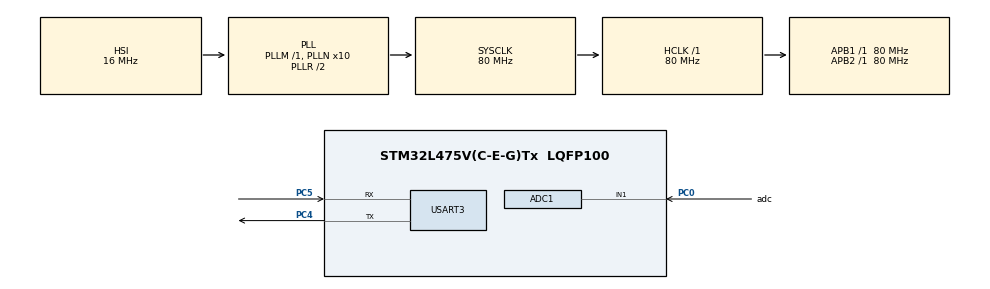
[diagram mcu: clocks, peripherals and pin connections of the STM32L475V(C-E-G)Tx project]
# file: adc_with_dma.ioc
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ADC1.Channel-0\#ChannelRegularConversion=ADC_CHANNEL_1
ADC1.ClockPrescaler=ADC_CLOCK_ASYNC_DIV256
ADC1.ContinuousConvMode=ENABLE
ADC1.DMAContinuousRequests=ENABLE
ADC1.NbrOfConversionFlag=1
ADC1.OffsetNumber-0\#ChannelRegularConversion=ADC_OFFSET_NONE
ADC1.Rank-0\#ChannelRegularConversion=1
ADC1.SamplingTime-0\#ChannelRegularConversion=ADC_SAMPLETIME_92CYCLES_5
ADC1.master=1
Dma.ADC1.0.Direction=DMA_PERIPH_TO_MEMORY
Dma.ADC1.0.Instance=DMA1_Channel1
Dma.ADC1.0.MemDataAlignment=DMA_MDATAALIGN_WORD
Dma.ADC1.0.MemInc=DMA_MINC_ENABLE
Dma.ADC1.0.Mode=DMA_CIRCULAR
Dma.ADC1.0.PeriphDataAlignment=DMA_PDATAALIGN_WORD
Dma.ADC1.0.PeriphInc=DMA_PINC_DISABLE
Dma.ADC1.0.Priority=DMA_PRIORITY_LOW
Dma.Request0=ADC1
Mcu.Family=STM32L4
Mcu.Name=STM32L475V(C-E-G)Tx
Mcu.Package=LQFP100
NVIC.DMA1_Channel1_IRQn=true\:0\:0\:false\:false\:true\:false\:true\:true
NVIC.PriorityGroup=NVIC_PRIORITYGROUP_4
PA13\ (JTMS-SWDIO).Mode=Serial_Wire
PA13\ (JTMS-SWDIO).Signal=SYS_JTMS-SWDIO
PA14\ (JTCK-SWCLK).Mode=Serial_Wire
PA14\ (JTCK-SWCLK).Signal=SYS_JTCK-SWCLK
PC0.GPIO_Label=adc
PC0.Signal=ADCx_IN1
PC4.Mode=Asynchronous
PC4.Signal=USART3_TX
PC5.Mode=Asynchronous
PC5.Signal=USART3_RX
ProjectManager.HeapSize=0x200
ProjectManager.StackSize=0x400
ProjectManager.TargetToolchain=STM32CubeIDE
RCC.ADCFreq_Value=64000000
RCC.AHBFreq_Value=80000000
RCC.APB1Freq_Value=80000000
RCC.APB1TimFreq_Value=80000000
RCC.APB2Freq_Value=80000000
RCC.APB2TimFreq_Value=80000000
RCC.CortexFreq_Value=80000000
RCC.HCLKFreq_Value=80000000
RCC.HSE_VALUE=8000000
RCC.HSI_VALUE=16000000
RCC.LSE_VALUE=32768
RCC.MSI_VALUE=4000000
RCC.PLLN=10
RCC.PLLSourceVirtual=RCC_PLLSOURCE_HSI
RCC.SYSCLKFreq_VALUE=80000000
RCC.SYSCLKSource=RCC_SYSCLKSOURCE_PLLCLK
RCC.USBFreq_Value=64000000
RCC.VCOOutputFreq_Value=160000000
SH.ADCx_IN1.0=ADC1_IN1,IN1-Single-Ended
USART3.VirtualMode-Asynchronous=VM_ASYNC
board=B-L475E-IOT01A2

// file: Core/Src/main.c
/* USER CODE BEGIN Header */
/**
  ******************************************************************************
  * @file           : main.c
  * @brief          : Main program body
  ******************************************************************************
  * @attention
  *
  * Copyright (c) 2024 STMicroelectronics.
  * All rights reserved.
  *
  * This software is licensed under terms that can be found in the LICENSE file
  * in the root directory of this software component.
  * If no LICENSE file comes with this software, it is provided AS-IS.
  *
  ******************************************************************************
  */
/* USER CODE END Header */
#include "main.h"
#include <stdlib.h>

ADC_HandleTypeDef hadc1;
DMA_HandleTypeDef hdma_adc1;

UART_HandleTypeDef huart3;

/* USER CODE BEGIN PV */
uint32_t adc_val;
uint32_t dma_buffer;
uint32_t time;
/* USER CODE END PV */

void SystemClock_Config(void);
static void MX_GPIO_Init(void);
static void MX_DMA_Init(void);
static void MX_ADC1_Init(void);
static void MX_USART3_UART_Init(void);

int main(void)
{

  /* MCU Configuration--------------------------------------------------------*/

  /* Reset of all peripherals, Initializes the Flash interface and the Systick. */
  HAL_Init();

  /* Configure the system clock */
  SystemClock_Config();

  /* Initialize all configured peripherals */
  MX_GPIO_Init();
  MX_DMA_Init();
  MX_ADC1_Init();
  MX_USART3_UART_Init();
  /* USER CODE BEGIN 2 */
  // Attaching the ADC1 to DMA.
  HAL_ADC_Start_DMA(&hadc1, &dma_buffer,1);
  /* USER CODE END 2 */

  /* Infinite loop */
  while (1)
  {
	  time = HAL_GetTick();
	  for(int i = 0; i < 1000000; i++)
	  {
		  // CPU load using a for loop.
	  }
	  time = HAL_GetTick() - time;

	  //Elapsed time calculation, CPU didn't get any interrupt for ADC.
	  // Send elapsed time to terminal using USART3
	  uint8_t time_str[] = "With DMA time: ";
	  HAL_UART_Transmit(&huart3, time_str, sizeof(time_str),10);
	  //Integer to char conversion
	  char time_buf[sizeof(uint32_t)*8+1];
	  utoa(time, time_buf, 10);
	  HAL_UART_Transmit(&huart3, (uint8_t*)time_buf,3,10);

	  // Send ADC value to terminal using USART3
	  uint8_t adc_str[] = " adc val: ";
	  HAL_UART_Transmit(&huart3, adc_str, sizeof(adc_str),10);

	  // Integer to char conversion.
	  char adc_buf[sizeof(uint32_t)*8+2+1];// size of uint32_t = 4bytes = 32 bits + 1 NULL char + \r \n
	  utoa(adc_val, adc_buf, 10);
	  adc_buf[5] = '\n';
	  adc_buf[4] = '\r';
	  HAL_UART_Transmit(&huart3, (uint8_t*)adc_buf, 6,10);
  }
}

void SystemClock_Config(void)
{
  RCC_OscInitTypeDef RCC_OscInitStruct = {0};
  RCC_ClkInitTypeDef RCC_ClkInitStruct = {0};

  /** Configure the main internal regulator output voltage
  */
  if (HAL_PWREx_ControlVoltageScaling(PWR_REGULATOR_VOLTAGE_SCALE1) != HAL_OK)
  {
    Error_Handler();
  }

  /** Initializes the RCC Oscillators according to the specified parameters
  * in the RCC_OscInitTypeDef structure.
  */
  RCC_OscInitStruct.OscillatorType = RCC_OSCILLATORTYPE_HSI;
  RCC_OscInitStruct.HSIState = RCC_HSI_ON;
  RCC_OscInitStruct.HSICalibrationValue = RCC_HSICALIBRATION_DEFAULT;
  RCC_OscInitStruct.PLL.PLLState = RCC_PLL_ON;
  RCC_OscInitStruct.PLL.PLLSource = RCC_PLLSOURCE_HSI;
  RCC_OscInitStruct.PLL.PLLM = 1;
  RCC_OscInitStruct.PLL.PLLN = 10;
  RCC_OscInitStruct.PLL.PLLP = RCC_PLLP_DIV7;
  RCC_OscInitStruct.PLL.PLLQ = RCC_PLLQ_DIV2;
  RCC_OscInitStruct.PLL.PLLR = RCC_PLLR_DIV2;
  if (HAL_RCC_OscConfig(&RCC_OscInitStruct) != HAL_OK)
  {
    Error_Handler();
  }

  /** Initializes the CPU, AHB and APB buses clocks
  */
  RCC_ClkInitStruct.ClockType = RCC_CLOCKTYPE_HCLK|RCC_CLOCKTYPE_SYSCLK
                              |RCC_CLOCKTYPE_PCLK1|RCC_CLOCKTYPE_PCLK2;
  RCC_ClkInitStruct.SYSCLKSource = RCC_SYSCLKSOURCE_PLLCLK;
  RCC_ClkInitStruct.AHBCLKDivider = RCC_SYSCLK_DIV1;
  RCC_ClkInitStruct.APB1CLKDivider = RCC_HCLK_DIV1;
  RCC_ClkInitStruct.APB2CLKDivider = RCC_HCLK_DIV1;

  if (HAL_RCC_ClockConfig(&RCC_ClkInitStruct, FLASH_LATENCY_4) != HAL_OK)
  {
    Error_Handler();
  }
}

static void MX_ADC1_Init(void)
{

  ADC_MultiModeTypeDef multimode = {0};
  ADC_ChannelConfTypeDef sConfig = {0};

  /** Common config
  */
  hadc1.Instance = ADC1;
  hadc1.Init.ClockPrescaler = ADC_CLOCK_ASYNC_DIV256;
  hadc1.Init.Resolution = ADC_RESOLUTION_12B;
  hadc1.Init.DataAlign = ADC_DATAALIGN_RIGHT;
  hadc1.Init.ScanConvMode = ADC_SCAN_DISABLE;
  hadc1.Init.EOCSelection = ADC_EOC_SINGLE_CONV;
  hadc1.Init.LowPowerAutoWait = DISABLE;
  hadc1.Init.ContinuousConvMode = ENABLE;
  hadc1.Init.NbrOfConversion = 1;
  hadc1.Init.DiscontinuousConvMode = DISABLE;
  hadc1.Init.ExternalTrigConv = ADC_SOFTWARE_START;
  hadc1.Init.ExternalTrigConvEdge = ADC_EXTERNALTRIGCONVEDGE_NONE;
  hadc1.Init.DMAContinuousRequests = ENABLE;
  hadc1.Init.Overrun = ADC_OVR_DATA_PRESERVED;
  hadc1.Init.OversamplingMode = DISABLE;
  if (HAL_ADC_Init(&hadc1) != HAL_OK)
  {
    Error_Handler();
  }

  /** Configure the ADC multi-mode
  */
  multimode.Mode = ADC_MODE_INDEPENDENT;
  if (HAL_ADCEx_MultiModeConfigChannel(&hadc1, &multimode) != HAL_OK)
  {
    Error_Handler();
  }

  /** Configure Regular Channel
  */
  sConfig.Channel = ADC_CHANNEL_1;
  sConfig.Rank = ADC_REGULAR_RANK_1;
  sConfig.SamplingTime = ADC_SAMPLETIME_92CYCLES_5;
  sConfig.SingleDiff = ADC_SINGLE_ENDED;
  sConfig.OffsetNumber = ADC_OFFSET_NONE;
  sConfig.Offset = 0;
  if (HAL_ADC_ConfigChannel(&hadc1, &sConfig) != HAL_OK)
  {
    Error_Handler();
  }

}

static void MX_USART3_UART_Init(void)
{

  huart3.Instance = USART3;
  huart3.Init.BaudRate = 115200;
  huart3.Init.WordLength = UART_WORDLENGTH_8B;
  huart3.Init.StopBits = UART_STOPBITS_1;
  huart3.Init.Parity = UART_PARITY_NONE;
  huart3.Init.Mode = UART_MODE_TX_RX;
  huart3.Init.HwFlowCtl = UART_HWCONTROL_NONE;
  huart3.Init.OverSampling = UART_OVERSAMPLING_16;
  huart3.Init.OneBitSampling = UART_ONE_BIT_SAMPLE_DISABLE;
  huart3.AdvancedInit.AdvFeatureInit = UART_ADVFEATURE_NO_INIT;
  if (HAL_UART_Init(&huart3) != HAL_OK)
  {
    Error_Handler();
  }

}

static void MX_DMA_Init(void)
{

  /* DMA controller clock enable */
  __HAL_RCC_DMA1_CLK_ENABLE();

  /* DMA interrupt init */
  /* DMA1_Channel1_IRQn interrupt configuration */
  HAL_NVIC_SetPriority(DMA1_Channel1_IRQn, 0, 0);
  HAL_NVIC_EnableIRQ(DMA1_Channel1_IRQn);

}

static void MX_GPIO_Init(void)
{

  /* GPIO Ports Clock Enable */
  __HAL_RCC_GPIOC_CLK_ENABLE();
  __HAL_RCC_GPIOA_CLK_ENABLE();

}

/* USER CODE BEGIN 4 */
void HAL_ADC_ConvCpltCallback(ADC_HandleTypeDef *hadc)
{
  /* Prevent unused argument(s) compilation warning */
	// Here the Interrupt is taken care by DMA therefore no CPU interrupts.
	// Still having a loop of 1000 for parity.
	  for(int i = 0; i < 1000; i++)
	  {
		  adc_val = dma_buffer;
	  }

  /* NOTE : This function should not be modified. When the callback is needed,
            function HAL_ADC_ConvHalfCpltCallback must be implemented in the user file.
  */
}
/* USER CODE END 4 */

void Error_Handler(void)
{
  __disable_irq();
  while (1)
  {
  }
}
